AUTOSAR XML (schema 314)
package /ComponentType
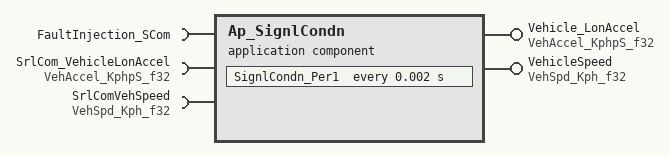
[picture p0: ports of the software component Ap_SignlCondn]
  application software component type Ap_SignlCondn
    provide port Vehicle_LonAccel: unqueued-sender-com-spec{data-element=KphpS_f32, can-invalidate=false, init-value=D_ZERO_ULS_F32}, provided-interface=VehAccel_KphpS_f32
    provide port VehicleSpeed: unqueued-sender-com-spec{data-element=Kph_f32, can-invalidate=false, init-value=D_ZERO_ULS_F32}, provided-interface=VehSpd_Kph_f32
    require port FaultInjection_SCom: client-com-spec=FltInjection, required-interface=FaultInjection_SCom
    require port SrlCom_VehicleLonAccel: unqueued-receiver-com-spec{data-element=KphpS_f32, init-value=D_ZERO_ULS_F32}, required-interface=VehAccel_KphpS_f32
    require port SrlComVehSpeed: unqueued-receiver-com-spec{data-element=Kph_f32, init-value=D_ZERO_ULS_F32}, required-interface=VehSpd_Kph_f32
  internal behavior Ap_SignlCondn_InternalBehavior: component=Ap_SignlCondn
    timing event TMT_SignlCondn_Per1: start-on-event=SignlCondn_Per1, period=0.002
    port-api-options:
      enable-take-address=false, indirect-api=false, port=FaultInjection_SCom
      enable-take-address=false, indirect-api=false, port=SrlCom_VehicleLonAccel
      enable-take-address=false, indirect-api=false, port=SrlComVehSpeed
      enable-take-address=false, indirect-api=false, port=Vehicle_LonAccel
      enable-take-address=false, indirect-api=false, port=VehicleSpeed
    runnable SignlCondn_Per1
      data read access READ_SrlCom_VehicleLonAccel_KphpS_f32: data-element=SrlCom_VehicleLonAccel.KphpS_f32
      data read access READ_SrlComVehSpeed_Kph_f32: data-element=SrlComVehSpeed.Kph_f32
      data write access WRITE_Vehicle_LonAccel_KphpS_f32: data-element=Vehicle_LonAccel.KphpS_f32
      data write access WRITE_VehicleSpeed_Kph_f32: data-element=VehicleSpeed.Kph_f32
      sync call SC_FaultInjection_SCom_FltInjection: operation=FaultInjection_SCom.FltInjection, timeout=0
  swc implementation Ap_SignlCondn_Implementation: behavior=Ap_SignlCondn_InternalBehavior
    code-descriptors:
      code Code: type=SRC
